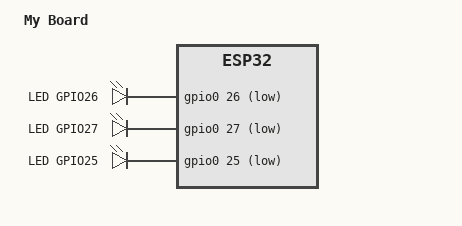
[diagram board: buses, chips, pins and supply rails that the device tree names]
/dts-v1/;

#include <espressif/esp32/esp32_appcpu.dtsi>
#include <espressif/partitions_0x1000_amp.dtsi>

/ {
	model = "My Board";
	compatible = "Chrisesis,my_board";

	aliases {
		led0 = &red_led;
		led1 = &green_led;
		led2 = &blue_led;
	};

	chosen {
		zephyr,sram = &sram0;
		zephyr,flash = &flash;
		zephyr,code-partition = &slot0_partition;
	};

	leds{

		compatible = "gpio-leds";
		red_led: led_0{
			gpios = <&gpio0 26 GPIO_ACTIVE_LOW>;
			label = "LED GPIO26";
		};
		green_led: led_1 {
			gpios = <&gpio0 27 GPIO_ACTIVE_LOW>;
			label = "LED GPIO27";
		};
		blue_led: led_2 {
			gpios = <&gpio0 25 GPIO_ACTIVE_LOW>;
			label = "LED GPIO25";
		};



	};
};
	&gpio0 {
			status = "okay";
		};



